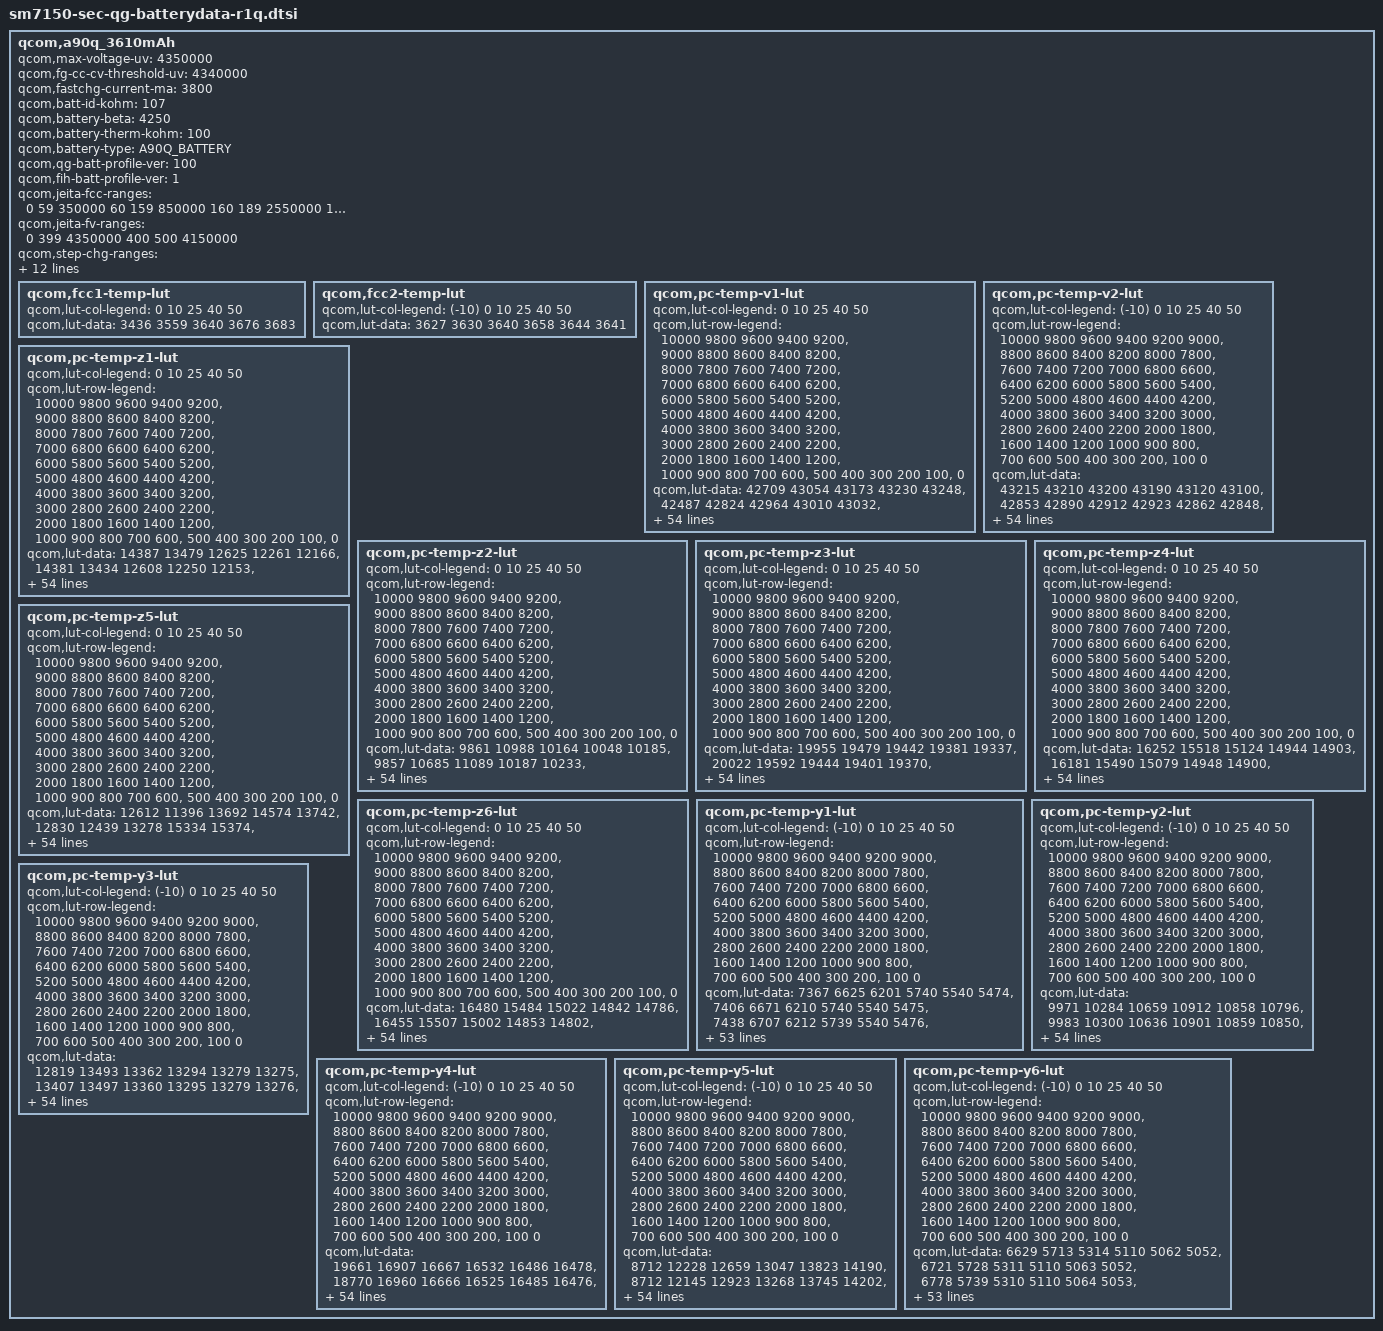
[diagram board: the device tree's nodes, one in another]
/*
 * Copyright (c) 2018, The Linux Foundation. All rights reserved.
 *
 * This program is free software; you can redistribute it and/or modify
 * it under the terms of the GNU General Public License version 2 and
 * only version 2 as published by the Free Software Foundation.
 *
 * This program is distributed in the hope that it will be useful,
 * but WITHOUT ANY WARRANTY; without even the implied warranty of
 * MERCHANTABILITY or FITNESS FOR A PARTICULAR PURPOSE.  See the
 * GNU General Public License for more details.
 */

qcom,a90q_3610mAh { /* A9S Battery is used for this (3720mAh) */
	/* A70Q BATTERY */
	qcom,max-voltage-uv = <4350000>;
	qcom,fg-cc-cv-threshold-uv = <4340000>;
	qcom,fastchg-current-ma = <3800>;
	qcom,batt-id-kohm = <107>;
	qcom,battery-beta = <4250>;
	qcom,battery-therm-kohm = <100>;
	qcom,battery-type = "A90Q_BATTERY";
	qcom,qg-batt-profile-ver = <100>;
	qcom,fih-batt-profile-ver = <1>;

	qcom,jeita-fcc-ranges = <0  59   350000
				60  159  850000
				160 189  2550000
				190 399  3800000
				400 490  1250000>;

	qcom,jeita-fv-ranges = <0   399  4350000
				400 500  4150000>;

	qcom,step-chg-ranges = <3400000  4299999  3800000
				4300000  4319999  3200000
				4320000  4350000  2550000>;
	qcom,vbat-avg-based-step-chg;
	qcom,taper-fcc;

	/* COOL = 18 DegC, WARM = 41 DegC */
	qcom,jeita-soft-thresholds = <0x4205 0x24EC>;
	/* COLD = 0 DegC, HOT = 50 DegC */
	qcom,jeita-hard-thresholds = <0x57F0 0x1C52>;

	qcom,qg-batt-aging-enable;
	qcom,vfloat-ranges = <0 299 4350000
				300 399 4330000
				400 699 4310000
				700 999 4290000
				1000 9999 4240000>;

	qcom,vbat-rechg-ranges = <0 299 4280000
				300 399 4260000
				400 699 4240000
				700 999 4220000
				1000 9999 4170000>;

	qcom,full-condition-soc-ranges = <0 299 93
				300 399 92
				400 699 91
				700 999 90
				1000 9999 89>;

	qcom,fcc1-temp-lut {
		qcom,lut-col-legend = <0 10 25 40 50>;
		qcom,lut-data = <3436 3559 3640 3676 3683>;
	};

	qcom,fcc2-temp-lut {
		qcom,lut-col-legend = <(-10) 0 10 25 40 50>;
		qcom,lut-data = <3627 3630 3640 3658 3644 3641>;
	};

	qcom,pc-temp-v1-lut {
		qcom,lut-col-legend = <0 10 25 40 50>;
		qcom,lut-row-legend = <10000 9800 9600 9400 9200>,
			<9000 8800 8600 8400 8200>,
			<8000 7800 7600 7400 7200>,
			<7000 6800 6600 6400 6200>,
			<6000 5800 5600 5400 5200>,
			<5000 4800 4600 4400 4200>,
			<4000 3800 3600 3400 3200>,
			<3000 2800 2600 2400 2200>,
			<2000 1800 1600 1400 1200>,
			<1000 900 800 700 600>,
			<500 400 300 200 100>,
			<0>;
		qcom,lut-data = <42709 43054 43173 43230 43248>,
			<42487 42824 42964 43010 43032>,
			<42271 42587 42744 42789 42815>,
			<42062 42354 42516 42568 42596>,
			<41857 42136 42288 42347 42376>,
			<41654 41924 42064 42127 42157>,
			<41457 41716 41843 41908 41937>,
			<41273 41506 41628 41692 41719>,
			<41114 41307 41417 41477 41508>,
			<40951 41130 41212 41266 41301>,
			<40745 40970 41022 41064 41097>,
			<40484 40788 40839 40874 40897>,
			<40242 40553 40648 40684 40701>,
			<40063 40309 40440 40488 40510>,
			<39912 40120 40238 40292 40322>,
			<39776 39969 40068 40115 40145>,
			<39653 39830 39917 39959 39985>,
			<39538 39701 39770 39807 39830>,
			<39423 39579 39630 39652 39671>,
			<39311 39443 39480 39495 39513>,
			<39200 39290 39272 39308 39336>,
			<39091 39125 38995 39060 39108>,
			<38981 38941 38787 38842 38889>,
			<38875 38738 38680 38721 38754>,
			<38769 38593 38601 38636 38657>,
			<38668 38512 38526 38552 38567>,
			<38578 38452 38459 38466 38475>,
			<38496 38402 38395 38386 38387>,
			<38425 38360 38335 38310 38305>,
			<38368 38322 38277 38239 38226>,
			<38322 38283 38223 38176 38157>,
			<38282 38247 38172 38120 38100>,
			<38249 38213 38125 38069 38048>,
			<38219 38182 38082 38017 37993>,
			<38188 38151 38044 37969 37938>,
			<38156 38115 38004 37920 37882>,
			<38119 38077 37967 37876 37827>,
			<38071 38029 37925 37828 37769>,
			<38003 37954 37856 37758 37695>,
			<37921 37856 37758 37664 37603>,
			<37818 37750 37650 37558 37499>,
			<37691 37630 37532 37440 37385>,
			<37551 37495 37401 37310 37259>,
			<37406 37340 37250 37162 37110>,
			<37290 37221 37131 37049 36993>,
			<37221 37153 37065 36979 36923>,
			<37203 37130 37044 36959 36904>,
			<37181 37110 37027 36946 36887>,
			<37151 37088 37008 36920 36862>,
			<37054 37010 36927 36824 36758>,
			<36767 36713 36622 36502 36430>,
			<36315 36268 36183 36060 35980>,
			<35747 35698 35619 35489 35400>,
			<34984 34932 34839 34717 34628>,
			<33764 33687 33622 33503 33403>,
			<30000 30000 30000 30000 30000>;
	};

	qcom,pc-temp-v2-lut {
		qcom,lut-col-legend = <(-10) 0 10 25 40 50>;
		qcom,lut-row-legend = <10000 9800 9600 9400 9200 9000>,
			<8800 8600 8400 8200 8000 7800>,
			<7600 7400 7200 7000 6800 6600>,
			<6400 6200 6000 5800 5600 5400>,
			<5200 5000 4800 4600 4400 4200>,
			<4000 3800 3600 3400 3200 3000>,
			<2800 2600 2400 2200 2000 1800>,
			<1600 1400 1200 1000 900 800>,
			<700 600 500 400 300 200>,
			<100 0>;
		qcom,lut-data = <43215 43210 43200 43190 43120 43100>,
			<42853 42890 42912 42923 42862 42848>,
			<42537 42595 42643 42668 42615 42606>,
			<42277 42330 42393 42428 42380 42373>,
			<42071 42092 42163 42203 42157 42150>,
			<41866 41866 41943 41983 41939 41932>,
			<41601 41637 41723 41764 41721 41715>,
			<41322 41415 41509 41549 41506 41500>,
			<41147 41213 41303 41337 41296 41290>,
			<41064 41042 41104 41126 41089 41082>,
			<40972 40869 40909 40922 40888 40880>,
			<40706 40661 40715 40730 40695 40687>,
			<40219 40423 40521 40545 40507 40499>,
			<39849 40188 40324 40357 40322 40317>,
			<39635 39956 40117 40156 40133 40138>,
			<39459 39734 39912 39965 39951 39965>,
			<39293 39545 39713 39806 39793 39804>,
			<39143 39378 39518 39666 39653 39656>,
			<38986 39211 39327 39501 39490 39487>,
			<38796 39028 39132 39275 39270 39269>,
			<38604 38849 38948 39043 39039 39044>,
			<38463 38696 38794 38863 38860 38866>,
			<38351 38563 38662 38711 38712 38718>,
			<38262 38440 38541 38581 38585 38590>,
			<38192 38320 38430 38472 38475 38479>,
			<38134 38207 38329 38376 38378 38382>,
			<38080 38116 38238 38286 38290 38292>,
			<38029 38041 38156 38202 38209 38209>,
			<37981 37980 38080 38125 38133 38132>,
			<37937 37935 38003 38054 38063 38060>,
			<37895 37897 37931 37988 37997 37994>,
			<37852 37861 37873 37927 37936 37932>,
			<37808 37828 37828 37871 37885 37880>,
			<37762 37793 37789 37814 37827 37820>,
			<37714 37753 37753 37756 37750 37730>,
			<37664 37708 37718 37697 37655 37613>,
			<37608 37658 37677 37634 37567 37509>,
			<37545 37604 37625 37568 37487 37424>,
			<37474 37541 37563 37498 37409 37345>,
			<37397 37465 37489 37425 37333 37267>,
			<37310 37372 37401 37347 37258 37191>,
			<37222 37268 37300 37253 37170 37102>,
			<37138 37148 37180 37132 37047 36978>,
			<37054 37024 37057 37013 36932 36865>,
			<36970 36912 36946 36912 36850 36791>,
			<36881 36827 36885 36875 36816 36759>,
			<36833 36795 36862 36862 36802 36746>,
			<36776 36755 36835 36840 36782 36725>,
			<36700 36694 36791 36797 36739 36678>,
			<36564 36584 36684 36669 36586 36506>,
			<36317 36349 36395 36315 36236 36134>,
			<35913 35914 35904 35817 35744 35641>,
			<35333 35323 35276 35176 35107 35004>,
			<34486 34514 34428 34288 34231 34137>,
			<33135 33244 33241 32987 33047 32871>,
			<28302 29120 28300 28436 28562 28479>;
	};

	qcom,pc-temp-z1-lut {
		qcom,lut-col-legend = <0 10 25 40 50>;
		qcom,lut-row-legend = <10000 9800 9600 9400 9200>,
			<9000 8800 8600 8400 8200>,
			<8000 7800 7600 7400 7200>,
			<7000 6800 6600 6400 6200>,
			<6000 5800 5600 5400 5200>,
			<5000 4800 4600 4400 4200>,
			<4000 3800 3600 3400 3200>,
			<3000 2800 2600 2400 2200>,
			<2000 1800 1600 1400 1200>,
			<1000 900 800 700 600>,
			<500 400 300 200 100>,
			<0>;
		qcom,lut-data = <14387 13479 12625 12261 12166>,
			<14381 13434 12608 12250 12153>,
			<14383 13418 12596 12242 12145>,
			<14392 13411 12587 12238 12144>,
			<14399 13408 12580 12235 12143>,
			<14394 13404 12573 12233 12144>,
			<14382 13400 12567 12231 12145>,
			<14377 13394 12563 12231 12146>,
			<14395 13388 12559 12232 12148>,
			<14413 13382 12556 12234 12153>,
			<14401 13371 12554 12236 12156>,
			<14364 13359 12551 12238 12157>,
			<14341 13343 12549 12239 12159>,
			<14339 13329 12548 12239 12159>,
			<14337 13327 12548 12239 12160>,
			<14335 13331 12548 12239 12160>,
			<14332 13335 12551 12241 12162>,
			<14328 13336 12555 12243 12164>,
			<14325 13338 12559 12245 12166>,
			<14320 13339 12562 12248 12168>,
			<14318 13344 12565 12250 12170>,
			<14320 13350 12568 12253 12172>,
			<14318 13352 12571 12255 12174>,
			<14315 13353 12576 12258 12177>,
			<14305 13355 12582 12262 12180>,
			<14292 13363 12587 12265 12184>,
			<14288 13372 12593 12269 12187>,
			<14290 13376 12599 12273 12192>,
			<14291 13376 12605 12277 12196>,
			<14289 13377 12611 12282 12199>,
			<14287 13380 12614 12287 12203>,
			<14286 13384 12616 12291 12208>,
			<14286 13390 12618 12295 12212>,
			<14288 13398 12623 12299 12215>,
			<14291 13407 12630 12302 12217>,
			<14297 13419 12636 12306 12219>,
			<14304 13434 12643 12308 12222>,
			<14305 13445 12649 12311 12224>,
			<14299 13453 12656 12314 12227>,
			<14294 13463 12663 12319 12230>,
			<14301 13464 12668 12324 12234>,
			<14312 13459 12672 12329 12237>,
			<14304 13459 12676 12334 12240>,
			<14283 13460 12682 12337 12244>,
			<14283 13451 12702 12343 12249>,
			<14273 13448 12700 12349 12251>,
			<14282 13449 12699 12348 12252>,
			<14263 13455 12699 12350 12255>,
			<14257 13458 12699 12351 12257>,
			<14276 13461 12706 12358 12260>,
			<14288 13478 12715 12365 12267>,
			<14289 13495 12730 12376 12277>,
			<14306 13528 12749 12391 12291>,
			<14328 13547 12783 12412 12310>,
			<14328 13547 12783 12412 12310>,
			<14328 13547 12783 12412 12310>;
	};

	qcom,pc-temp-z2-lut {
		qcom,lut-col-legend = <0 10 25 40 50>;
		qcom,lut-row-legend = <10000 9800 9600 9400 9200>,
			<9000 8800 8600 8400 8200>,
			<8000 7800 7600 7400 7200>,
			<7000 6800 6600 6400 6200>,
			<6000 5800 5600 5400 5200>,
			<5000 4800 4600 4400 4200>,
			<4000 3800 3600 3400 3200>,
			<3000 2800 2600 2400 2200>,
			<2000 1800 1600 1400 1200>,
			<1000 900 800 700 600>,
			<500 400 300 200 100>,
			<0>;
		qcom,lut-data = <9861 10988 10164 10048 10185>,
			<9857 10685 11089 10187 10233>,
			<9861 10236 11226 10328 10254>,
			<9871 9954 11043 10590 10274>,
			<9881 9926 10827 10838 10271>,
			<9895 9914 10620 10859 10254>,
			<9912 9905 10443 11005 10265>,
			<9921 9898 10396 11169 10274>,
			<9925 9895 10380 11184 10219>,
			<9927 9928 10373 11188 10112>,
			<9917 10017 10458 11181 10074>,
			<9874 10057 10610 11155 10090>,
			<9843 9995 10636 11135 10111>,
			<9845 9913 10417 11158 10121>,
			<9854 9901 10189 11200 10127>,
			<9862 9919 10167 11141 10136>,
			<9869 9942 10172 10605 10154>,
			<9874 9968 10178 10158 10175>,
			<9874 9997 10193 10181 10194>,
			<9865 10016 10214 10265 10215>,
			<9855 10027 10231 10290 10224>,
			<9852 10035 10249 10262 10214>,
			<9850 10042 10258 10230 10202>,
			<9851 10049 10243 10210 10210>,
			<9856 10053 10218 10185 10246>,
			<9865 10055 10215 10190 10270>,
			<9874 10056 10234 10240 10254>,
			<9882 10056 10255 10294 10232>,
			<9889 10053 10271 10323 10246>,
			<9896 10050 10285 10351 10291>,
			<9902 10051 10287 10354 10313>,
			<9908 10055 10285 10322 10236>,
			<9914 10059 10283 10291 10131>,
			<9919 10067 10284 10291 10122>,
			<9925 10076 10290 10302 10159>,
			<9932 10082 10294 10318 10202>,
			<9941 10088 10299 10351 10251>,
			<9949 10095 10306 10391 10297>,
			<9958 10104 10318 10422 10311>,
			<9969 10114 10336 10453 10317>,
			<9985 10123 10348 10467 10319>,
			<10007 10129 10354 10462 10318>,
			<10039 10141 10360 10450 10317>,
			<10106 10168 10366 10364 10322>,
			<10446 10344 10431 10369 10343>,
			<10387 10415 10446 10363 10305>,
			<10336 10422 10434 10358 10328>,
			<10313 10453 10439 10385 10320>,
			<10262 10588 10468 10398 10375>,
			<10248 10614 10488 10481 10406>,
			<10242 10508 10554 10408 10218>,
			<10142 10498 10509 10325 10133>,
			<10015 10448 10529 10273 10077>,
			<9842 10332 10473 10229 10048>,
			<9842 10332 10473 10229 10048>,
			<9842 10332 10473 10229 10048>;
	};

	qcom,pc-temp-z3-lut {
		qcom,lut-col-legend = <0 10 25 40 50>;
		qcom,lut-row-legend = <10000 9800 9600 9400 9200>,
			<9000 8800 8600 8400 8200>,
			<8000 7800 7600 7400 7200>,
			<7000 6800 6600 6400 6200>,
			<6000 5800 5600 5400 5200>,
			<5000 4800 4600 4400 4200>,
			<4000 3800 3600 3400 3200>,
			<3000 2800 2600 2400 2200>,
			<2000 1800 1600 1400 1200>,
			<1000 900 800 700 600>,
			<500 400 300 200 100>,
			<0>;
		qcom,lut-data = <19955 19479 19442 19381 19337>,
			<20022 19592 19444 19401 19370>,
			<20035 19705 19458 19417 19392>,
			<20033 19762 19499 19431 19400>,
			<20024 19769 19529 19443 19404>,
			<20004 19771 19538 19453 19405>,
			<19974 19772 19544 19473 19409>,
			<19945 19769 19547 19487 19414>,
			<19912 19767 19546 19488 19409>,
			<19887 19770 19546 19488 19395>,
			<19903 19780 19552 19485 19386>,
			<19983 19784 19560 19471 19382>,
			<20042 19776 19556 19460 19380>,
			<20028 19761 19527 19456 19378>,
			<19986 19742 19495 19454 19377>,
			<19951 19716 19479 19446 19375>,
			<19927 19693 19467 19413 19366>,
			<19910 19676 19463 19386 19358>,
			<19910 19662 19464 19386 19358>,
			<19933 19660 19467 19388 19361>,
			<19966 19680 19475 19389 19363>,
			<19993 19702 19491 19391 19361>,
			<20022 19713 19501 19393 19356>,
			<20040 19722 19494 19386 19350>,
			<20046 19724 19482 19371 19341>,
			<20050 19722 19475 19366 19337>,
			<20051 19717 19469 19371 19348>,
			<20043 19711 19467 19379 19365>,
			<20031 19703 19470 19392 19380>,
			<20018 19694 19478 19410 19397>,
			<20002 19688 19484 19416 19404>,
			<19985 19682 19491 19415 19396>,
			<19965 19676 19495 19412 19384>,
			<19944 19670 19493 19409 19376>,
			<19924 19664 19490 19403 19371>,
			<19903 19659 19485 19398 19368>,
			<19884 19654 19479 19393 19365>,
			<19867 19650 19472 19388 19364>,
			<19852 19646 19467 19386 19363>,
			<19837 19642 19463 19383 19363>,
			<19819 19636 19461 19382 19363>,
			<19798 19626 19459 19384 19362>,
			<19774 19615 19457 19387 19361>,
			<19736 19602 19451 19378 19362>,
			<19575 19537 19431 19364 19357>,
			<19488 19494 19416 19359 19348>,
			<19381 19485 19410 19358 19337>,
			<19354 19472 19408 19347 19337>,
			<19340 19426 19393 19344 19327>,
			<19340 19419 19386 19335 19330>,
			<19357 19462 19380 19347 19356>,
			<19364 19451 19381 19349 19360>,
			<19371 19442 19359 19353 19358>,
			<19372 19358 19356 19348 19360>,
			<19372 19358 19356 19348 19360>,
			<19372 19358 19356 19348 19360>;
	};

	qcom,pc-temp-z4-lut {
		qcom,lut-col-legend = <0 10 25 40 50>;
		qcom,lut-row-legend = <10000 9800 9600 9400 9200>,
			<9000 8800 8600 8400 8200>,
			<8000 7800 7600 7400 7200>,
			<7000 6800 6600 6400 6200>,
			<6000 5800 5600 5400 5200>,
			<5000 4800 4600 4400 4200>,
			<4000 3800 3600 3400 3200>,
			<3000 2800 2600 2400 2200>,
			<2000 1800 1600 1400 1200>,
			<1000 900 800 700 600>,
			<500 400 300 200 100>,
			<0>;
		qcom,lut-data = <16252 15518 15124 14944 14903>,
			<16181 15490 15079 14948 14900>,
			<16076 15380 15025 14938 14894>,
			<15936 15267 14962 14905 14877>,
			<15819 15183 14910 14856 14849>,
			<15742 15112 14876 14815 14825>,
			<15679 15057 14848 14769 14801>,
			<15620 15018 14821 14729 14780>,
			<15566 14979 14797 14704 14769>,
			<15512 14920 14773 14686 14761>,
			<15450 14848 14733 14675 14753>,
			<15381 14819 14691 14667 14741>,
			<15324 14842 14683 14662 14731>,
			<15291 14873 14717 14656 14722>,
			<15267 14876 14753 14651 14714>,
			<15242 14857 14752 14652 14708>,
			<15215 14834 14739 14676 14703>,
			<15185 14813 14729 14699 14700>,
			<15145 14791 14722 14704 14700>,
			<15084 14779 14717 14707 14703>,
			<15021 14773 14741 14720 14711>,
			<14971 14769 14830 14799 14778>,
			<14924 14791 14881 14868 14854>,
			<14896 14859 14880 14871 14862>,
			<14887 14894 14876 14868 14858>,
			<14881 14889 14870 14863 14852>,
			<14880 14878 14856 14845 14828>,
			<14880 14866 14839 14818 14794>,
			<14880 14852 14818 14789 14762>,
			<14877 14836 14794 14754 14729>,
			<14868 14823 14772 14731 14710>,
			<14857 14811 14752 14716 14704>,
			<14849 14799 14737 14708 14700>,
			<14840 14787 14731 14708 14700>,
			<14832 14777 14726 14710 14703>,
			<14826 14769 14724 14712 14707>,
			<14820 14761 14723 14713 14709>,
			<14814 14758 14723 14715 14712>,
			<14808 14759 14727 14720 14716>,
			<14804 14761 14736 14729 14723>,
			<14805 14761 14740 14734 14726>,
			<14807 14757 14732 14724 14721>,
			<14801 14753 14725 14717 14716>,
			<14789 14745 14723 14725 14716>,
			<14781 14721 14702 14710 14705>,
			<14872 14731 14684 14687 14683>,
			<14984 14734 14678 14674 14678>,
			<15011 14740 14667 14664 14657>,
			<15017 14784 14675 14654 14647>,
			<15010 14788 14687 14674 14654>,
			<15002 14756 14719 14695 14664>,
			<15016 14777 14723 14699 14665>,
			<15024 14796 14749 14696 14670>,
			<15042 14896 14762 14704 14669>,
			<15042 14896 14762 14704 14669>,
			<15042 14896 14762 14704 14669>;
	};

	qcom,pc-temp-z5-lut {
		qcom,lut-col-legend = <0 10 25 40 50>;
		qcom,lut-row-legend = <10000 9800 9600 9400 9200>,
			<9000 8800 8600 8400 8200>,
			<8000 7800 7600 7400 7200>,
			<7000 6800 6600 6400 6200>,
			<6000 5800 5600 5400 5200>,
			<5000 4800 4600 4400 4200>,
			<4000 3800 3600 3400 3200>,
			<3000 2800 2600 2400 2200>,
			<2000 1800 1600 1400 1200>,
			<1000 900 800 700 600>,
			<500 400 300 200 100>,
			<0>;
		qcom,lut-data = <12612 11396 13692 14574 13742>,
			<12830 12439 13278 15334 15374>,
			<12961 13754 13428 16023 16461>,
			<13058 14738 14443 16574 16860>,
			<13095 15151 15665 17139 17062>,
			<13080 15436 16674 18059 17216>,
			<13040 15754 17654 20284 17887>,
			<12986 16075 18585 23033 18587>,
			<12886 16468 19509 26018 18278>,
			<12799 17249 20647 28895 17391>,
			<13021 18531 23747 29906 17091>,
			<13953 19342 28129 30151 17450>,
			<14623 19587 29133 30462 17998>,
			<14504 19630 24528 31632 18677>,
			<14147 19326 19751 33385 19539>,
			<13957 18576 19355 33061 19853>,
			<13959 18093 19619 26653 19685>,
			<13989 18376 20068 21225 19486>,
			<14147 19334 21816 21891 20171>,
			<14982 21293 24863 24000 22449>,
			<16259 28659 29559 25229 23537>,
			<17986 36858 37103 25714 22540>,
			<20833 40976 40829 25663 20839>,
			<23935 43964 36142 23374 18985>,
			<27400 44991 28441 18911 16343>,
			<30867 42402 24499 17025 15204>,
			<32870 37915 22075 16746 15524>,
			<34169 34643 21019 16767 16212>,
			<34928 31900 21296 17702 17924>,
			<34759 30002 22109 20198 22076>,
			<33728 29027 23422 22658 24292>,
			<32429 28309 26639 25004 24312>,
			<30905 27941 29869 27110 24306>,
			<29074 27786 32012 28659 24625>,
			<27576 27735 33786 29976 25834>,
			<26239 27893 34176 30414 26555>,
			<25129 28342 32805 29459 26384>,
			<24630 28565 30856 27784 25962>,
			<24628 28755 29122 25866 25124>,
			<24723 29057 27352 23296 23062>,
			<24356 28791 26482 22194 21414>,
			<23716 26850 26212 22677 20824>,
			<23955 26171 25913 23014 20474>,
			<24096 26435 24552 20292 20092>,
			<20016 25197 24934 19795 19929>,
			<16439 20063 23741 20132 19448>,
			<12763 18793 22567 20558 17818>,
			<11913 17839 22990 19351 19941>,
			<11769 15537 20310 20354 20305>,
			<11848 15735 18599 16727 18692>,
			<12045 16845 16007 15571 18755>,
			<11985 15424 15626 15040 18414>,
			<11908 14587 13828 15042 16934>,
			<11724 12129 13273 14188 16576>,
			<11724 12129 13273 14188 16576>,
			<11724 12129 13273 14188 16576>;
	};

	qcom,pc-temp-z6-lut {
		qcom,lut-col-legend = <0 10 25 40 50>;
		qcom,lut-row-legend = <10000 9800 9600 9400 9200>,
			<9000 8800 8600 8400 8200>,
			<8000 7800 7600 7400 7200>,
			<7000 6800 6600 6400 6200>,
			<6000 5800 5600 5400 5200>,
			<5000 4800 4600 4400 4200>,
			<4000 3800 3600 3400 3200>,
			<3000 2800 2600 2400 2200>,
			<2000 1800 1600 1400 1200>,
			<1000 900 800 700 600>,
			<500 400 300 200 100>,
			<0>;
		qcom,lut-data = <16480 15484 15022 14842 14786>,
			<16455 15507 15002 14853 14802>,
			<16406 15496 14988 14857 14810>,
			<16326 15480 14978 14850 14806>,
			<16251 15449 14969 14836 14797>,
			<16194 15405 14958 14825 14789>,
			<16143 15372 14946 14816 14782>,
			<16093 15349 14934 14807 14774>,
			<16038 15327 14923 14798 14766>,
			<15994 15300 14911 14791 14757>,
			<15980 15270 14898 14782 14749>,
			<15975 15256 14884 14772 14742>,
			<15969 15253 14876 14763 14736>,
			<15949 15251 14873 14759 14731>,
			<15911 15244 14870 14756 14727>,
			<15878 15221 14863 14751 14723>,
			<15853 15196 14851 14742 14715>,
			<15832 15177 14845 14737 14710>,
			<15814 15161 14844 14737 14710>,
			<15799 15158 14843 14740 14712>,
			<15787 15164 14856 14747 14718>,
			<15779 15175 14904 14783 14746>,
			<15773 15195 14932 14814 14776>,
			<15769 15230 14929 14813 14778>,
			<15768 15246 14923 14805 14773>,
			<15767 15243 14916 14799 14767>,
			<15764 15238 14909 14794 14763>,
			<15758 15232 14901 14789 14758>,
			<15750 15223 14895 14784 14754>,
			<15740 15213 14889 14779 14750>,
			<15727 15205 14885 14774 14746>,
			<15714 15199 14880 14768 14738>,
			<15699 15192 14876 14762 14731>,
			<15684 15186 14874 14760 14728>,
			<15672 15180 14871 14758 14726>,
			<15660 15176 14868 14756 14725>,
			<15650 15173 14864 14755 14725>,
			<15643 15172 14862 14753 14726>,
			<15637 15173 14863 14754 14726>,
			<15630 15175 14866 14757 14729>,
			<15623 15175 14868 14759 14731>,
			<15615 15171 14865 14757 14729>,
			<15604 15167 14862 14755 14727>,
			<15585 15162 14860 14754 14728>,
			<15508 15124 14843 14742 14721>,
			<15501 15111 14828 14730 14708>,
			<15493 15107 14822 14724 14700>,
			<15491 15104 14817 14714 14691>,
			<15490 15102 14814 14709 14681>,
			<15492 15102 14817 14713 14686>,
			<15506 15117 14831 14731 14707>,
			<15526 15129 14836 14736 14712>,
			<15547 15142 14840 14740 14716>,
			<15578 15160 14851 14746 14721>,
			<15578 15160 14851 14746 14721>,
			<15578 15160 14851 14746 14721>;
	};

	qcom,pc-temp-y1-lut {
		qcom,lut-col-legend = <(-10) 0 10 25 40 50>;
		qcom,lut-row-legend = <10000 9800 9600 9400 9200 9000>,
			<8800 8600 8400 8200 8000 7800>,
			<7600 7400 7200 7000 6800 6600>,
			<6400 6200 6000 5800 5600 5400>,
			<5200 5000 4800 4600 4400 4200>,
			<4000 3800 3600 3400 3200 3000>,
			<2800 2600 2400 2200 2000 1800>,
			<1600 1400 1200 1000 900 800>,
			<700 600 500 400 300 200>,
			<100 0>;
		qcom,lut-data = <7367 6625 6201 5740 5540 5474>,
			<7406 6671 6210 5740 5540 5475>,
			<7438 6707 6212 5739 5540 5476>,
			<7462 6732 6210 5738 5539 5477>,
			<7477 6747 6206 5736 5539 5478>,
			<7483 6753 6204 5735 5538 5478>,
			<7476 6752 6202 5733 5538 5478>,
			<7462 6750 6197 5732 5537 5478>,
			<7454 6747 6195 5732 5536 5478>,
			<7449 6733 6193 5731 5536 5478>,
			<7446 6719 6192 5730 5535 5478>,
			<7447 6718 6192 5730 5536 5479>,
			<7451 6723 6191 5730 5537 5480>,
			<7457 6727 6191 5729 5537 5480>,
			<7471 6729 6191 5730 5538 5480>,
			<7485 6730 6192 5731 5538 5480>,
			<7483 6731 6195 5732 5539 5481>,
			<7469 6733 6200 5733 5542 5482>,
			<7463 6734 6202 5734 5543 5483>,
			<7474 6733 6204 5737 5543 5484>,
			<7486 6732 6205 5740 5542 5484>,
			<7481 6735 6204 5743 5543 5485>,
			<7456 6747 6203 5745 5544 5487>,
			<7438 6755 6203 5748 5546 5489>,
			<7445 6756 6204 5751 5549 5493>,
			<7460 6756 6205 5754 5552 5496>,
			<7469 6754 6207 5757 5554 5497>,
			<7471 6741 6210 5762 5555 5497>,
			<7470 6729 6215 5765 5557 5498>,
			<7460 6730 6218 5769 5561 5499>,
			<7445 6733 6222 5773 5566 5503>,
			<7439 6734 6225 5778 5570 5506>,
			<7436 6742 6228 5784 5573 5511>,
			<7435 6751 6230 5789 5575 5515>,
			<7433 6754 6232 5793 5579 5516>,
			<7432 6751 6234 5795 5582 5516>,
			<7430 6746 6236 5797 5584 5518>,
			<7439 6750 6239 5799 5585 5520>,
			<7448 6756 6242 5801 5587 5522>,
			<7443 6753 6244 5806 5588 5524>,
			<7423 6737 6247 5814 5589 5525>,
			<7408 6728 6250 5818 5591 5527>,
			<7423 6728 6256 5818 5595 5532>,
			<7454 6731 6257 5820 5599 5535>,
			<7427 6745 6260 5821 5601 5536>,
			<7408 6746 6262 5831 5604 5536>,
			<7417 6743 6258 5835 5606 5537>,
			<7408 6753 6259 5833 5606 5538>,
			<7428 6767 6272 5832 5604 5539>,
			<7450 6753 6275 5837 5603 5539>,
			<7440 6755 6273 5846 5612 5543>,
			<7449 6767 6285 5858 5622 5550>,
			<7474 6799 6305 5881 5633 5559>,
			<7568 6854 6338 5906 5648 5571>,
			<7568 6854 6338 5906 5648 5571>,
			<7568 6854 6338 5906 5648 5571>;
	};

	qcom,pc-temp-y2-lut {
		qcom,lut-col-legend = <(-10) 0 10 25 40 50>;
		qcom,lut-row-legend = <10000 9800 9600 9400 9200 9000>,
			<8800 8600 8400 8200 8000 7800>,
			<7600 7400 7200 7000 6800 6600>,
			<6400 6200 6000 5800 5600 5400>,
			<5200 5000 4800 4600 4400 4200>,
			<4000 3800 3600 3400 3200 3000>,
			<2800 2600 2400 2200 2000 1800>,
			<1600 1400 1200 1000 900 800>,
			<700 600 500 400 300 200>,
			<100 0>;
		qcom,lut-data = <9971 10284 10659 10912 10858 10796>,
			<9983 10300 10636 10901 10859 10850>,
			<10010 10311 10613 10888 10858 10879>,
			<10044 10318 10591 10874 10855 10890>,
			<10078 10321 10572 10861 10851 10888>,
			<10106 10321 10558 10849 10846 10881>,
			<10168 10313 10549 10815 10841 10856>,
			<10268 10302 10542 10764 10835 10814>,
			<10299 10304 10534 10754 10826 10796>,
			<10273 10368 10524 10775 10808 10790>,
			<10249 10438 10517 10792 10792 10786>,
			<10213 10463 10530 10787 10790 10780>,
			<10098 10485 10569 10777 10795 10771>,
			<10029 10492 10606 10779 10795 10766>,
			<9876 10500 10642 10791 10776 10764>,
			<9709 10515 10671 10808 10760 10768>,
			<9682 10536 10680 10836 10789 10802>,
			<9674 10573 10685 10881 10876 10878>,
			<9669 10607 10693 10905 10927 10918>,
			<9666 10638 10722 10912 10911 10918>,
			<9664 10666 10762 10917 10886 10913>,
			<9662 10681 10790 10937 10902 10921>,
			<9661 10695 10817 10974 10952 10941>,
			<9660 10703 10840 10999 10987 10963>,
			<9659 10714 10866 11020 11008 10984>,
			<9658 10734 10891 11042 11028 11009>,
			<9658 10748 10896 11057 11041 11038>,
			<9657 10770 10897 11069 11066 11075>,
			<9656 10777 10902 11076 11087 11095>,
			<9656 10669 10919 11076 11095 11071>,
			<9655 10387 10940 11076 11099 11034>,
			<9655 10238 10944 11079 11106 11045>,
			<9654 10218 10925 11091 11143 11222>,
			<9654 10199 10897 11098 11177 11388>,
			<9654 10104 10874 11081 11169 11349>,
			<9654 9913 10851 11056 11141 11193>,
			<9653 9792 10826 11053 11127 11105>,
			<9653 9724 10799 11064 11126 11091>,
			<9653 9683 10769 11073 11127 11085>,
			<9653 9673 10734 11070 11117 11081>,
			<9653 9668 10694 11059 11097 11072>,
			<9653 9664 10652 11048 11087 11064>,
			<9653 9660 10612 11038 11077 11065>,
			<9653 9658 10566 11009 11053 11058>,
			<9652 9656 10502 10941 11004 10971>,
			<9652 9654 10432 10937 10996 10886>,
			<9652 9654 10402 10925 10981 10827>,
			<9652 9653 10380 10948 10962 10796>,
			<9652 9653 10358 10930 10934 10779>,
			<9652 9653 10321 10920 10946 10792>,
			<9652 9652 10117 10862 10917 10773>,
			<9652 9652 9902 10804 10833 10699>,
			<9651 9651 9704 10743 10766 10627>,
			<9650 9651 9666 10629 10692 10518>,
			<9650 9651 9666 10629 10692 10518>,
			<9650 9651 9666 10629 10692 10518>;
	};

	qcom,pc-temp-y3-lut {
		qcom,lut-col-legend = <(-10) 0 10 25 40 50>;
		qcom,lut-row-legend = <10000 9800 9600 9400 9200 9000>,
			<8800 8600 8400 8200 8000 7800>,
			<7600 7400 7200 7000 6800 6600>,
			<6400 6200 6000 5800 5600 5400>,
			<5200 5000 4800 4600 4400 4200>,
			<4000 3800 3600 3400 3200 3000>,
			<2800 2600 2400 2200 2000 1800>,
			<1600 1400 1200 1000 900 800>,
			<700 600 500 400 300 200>,
			<100 0>;
		qcom,lut-data = <12819 13493 13362 13294 13279 13275>,
			<13407 13497 13360 13295 13279 13276>,
			<13781 13502 13361 13296 13280 13276>,
			<13989 13508 13363 13297 13280 13277>,
			<14078 13515 13366 13298 13281 13278>,
			<14099 13522 13369 13299 13281 13279>,
			<13980 13533 13371 13299 13281 13279>,
			<13729 13544 13375 13298 13282 13280>,
			<13643 13545 13377 13298 13283 13280>,
			<13682 13524 13381 13299 13286 13280>,
			<13725 13501 13386 13299 13289 13280>,
			<13720 13500 13391 13303 13291 13282>,
			<13691 13505 13395 13311 13292 13286>,
			<13664 13506 13397 13315 13292 13288>,
			<13606 13497 13395 13316 13291 13287>,
			<13549 13485 13392 13317 13289 13286>,
			<13549 13475 13387 13318 13290 13287>,
			<13572 13465 13380 13320 13295 13290>,
			<13586 13454 13372 13321 13298 13292>,
			<13573 13439 13362 13316 13293 13289>,
			<13550 13424 13353 13309 13287 13283>,
			<13540 13412 13349 13304 13284 13280>,
			<13535 13404 13347 13300 13282 13279>,
			<13540 13396 13345 13298 13281 13278>,
			<13565 13386 13340 13299 13281 13277>,
			<13605 13376 13335 13300 13281 13277>,
			<13642 13368 13335 13300 13281 13278>,
			<13678 13355 13337 13299 13282 13279>,
			<13718 13347 13338 13298 13283 13280>,
			<13764 13351 13334 13299 13283 13279>,
			<13816 13363 13329 13300 13283 13278>,
			<13869 13370 13326 13301 13283 13278>,
			<13925 13372 13328 13302 13284 13280>,
			<13985 13372 13330 13302 13285 13281>,
			<14048 13370 13335 13301 13285 13279>,
			<14115 13372 13341 13300 13285 13277>,
			<14188 13382 13344 13299 13284 13276>,
			<14269 13407 13344 13298 13282 13276>,
			<14357 13436 13344 13298 13280 13277>,
			<14446 13460 13344 13298 13280 13277>,
			<14538 13490 13345 13298 13282 13277>,
			<14631 13529 13347 13297 13283 13277>,
			<14722 13606 13352 13298 13283 13278>,
			<14817 13717 13357 13299 13282 13278>,
			<14927 13862 13362 13300 13283 13278>,
			<15061 14072 13374 13303 13288 13284>,
			<15123 14174 13380 13307 13290 13287>,
			<15073 14178 13383 13309 13295 13290>,
			<15139 14251 13394 13315 13297 13292>,
			<15294 14428 13405 13318 13295 13288>,
			<15479 14623 13416 13312 13293 13285>,
			<15747 14870 13437 13315 13296 13289>,
			<16146 15236 13494 13326 13299 13294>,
			<17279 15608 13622 13338 13303 13297>,
			<17279 15608 13622 13338 13303 13297>,
			<17279 15608 13622 13338 13303 13297>;
	};

	qcom,pc-temp-y4-lut {
		qcom,lut-col-legend = <(-10) 0 10 25 40 50>;
		qcom,lut-row-legend = <10000 9800 9600 9400 9200 9000>,
			<8800 8600 8400 8200 8000 7800>,
			<7600 7400 7200 7000 6800 6600>,
			<6400 6200 6000 5800 5600 5400>,
			<5200 5000 4800 4600 4400 4200>,
			<4000 3800 3600 3400 3200 3000>,
			<2800 2600 2400 2200 2000 1800>,
			<1600 1400 1200 1000 900 800>,
			<700 600 500 400 300 200>,
			<100 0>;
		qcom,lut-data = <19661 16907 16667 16532 16486 16478>,
			<18770 16960 16666 16525 16485 16476>,
			<18205 17003 16668 16523 16486 16476>,
			<17892 17037 16671 16523 16487 16476>,
			<17757 17059 16674 16526 16489 16477>,
			<17726 17069 16678 16530 16492 16478>,
			<17906 17062 16685 16536 16495 16480>,
			<18307 17045 16696 16545 16499 16484>,
			<18507 17052 16704 16554 16502 16487>,
			<18594 17197 16710 16562 16504 16492>,
			<18617 17351 16719 16570 16506 16497>,
			<18378 17367 16758 16577 16511 16501>,
			<17856 17315 16835 16585 16519 16504>,
			<17623 17260 16878 16593 16528 16509>,
			<17651 17170 16896 16604 16539 16518>,
			<17688 17077 16905 16618 16552 16530>,
			<17646 17040 16887 16645 16572 16545>,
			<17531 17020 16820 16685 16600 16565>,
			<17404 16994 16755 16699 16611 16573>,
			<17264 16945 16698 16647 16583 16553>,
			<17131 16888 16650 16577 16540 16522>,
			<17073 16850 16626 16543 16514 16503>,
			<17042 16823 16611 16519 16494 16487>,
			<17025 16796 16605 16508 16486 16481>,
			<17015 16753 16607 16507 16487 16481>,
			<17010 16709 16610 16507 16488 16482>,
			<17009 16698 16610 16510 16491 16485>,
			<17012 16701 16608 16519 16498 16490>,
			<17016 16707 16604 16527 16506 16498>,
			<17017 16716 16599 16534 16516 16507>,
			<17018 16732 16592 16542 16527 16518>,
			<17019 16750 16590 16547 16539 16529>,
			<17027 16768 16593 16552 16554 16543>,
			<17035 16785 16599 16554 16563 16552>,
			<17041 16810 16606 16548 16548 16538>,
			<17048 16846 16615 16536 16512 16502>,
			<17051 16867 16623 16524 16492 16483>,
			<17049 16876 16631 16512 16485 16478>,
			<17047 16883 16639 16505 16481 16476>,
			<17047 16891 16648 16508 16484 16477>,
			<17049 16899 16658 16518 16491 16483>,
			<17054 16901 16667 16526 16494 16487>,
			<17065 16896 16676 16532 16494 16485>,
			<17087 16892 16686 16532 16493 16481>,
			<17135 16908 16697 16526 16487 16476>,
			<17214 16963 16737 16551 16500 16492>,
			<17253 17012 16765 16566 16517 16514>,
			<17218 17044 16780 16580 16539 16545>,
			<17220 17089 16832 16613 16571 16569>,
			<17238 17148 16880 16620 16540 16530>,
			<17218 17172 16882 16566 16497 16486>,
			<17183 17158 16885 16576 16497 16489>,
			<17186 17158 16959 16611 16511 16500>,
			<17466 17205 17058 16694 16564 16554>,
			<17466 17205 17058 16694 16564 16554>,
			<17466 17205 17058 16694 16564 16554>;
	};

	qcom,pc-temp-y5-lut {
		qcom,lut-col-legend = <(-10) 0 10 25 40 50>;
		qcom,lut-row-legend = <10000 9800 9600 9400 9200 9000>,
			<8800 8600 8400 8200 8000 7800>,
			<7600 7400 7200 7000 6800 6600>,
			<6400 6200 6000 5800 5600 5400>,
			<5200 5000 4800 4600 4400 4200>,
			<4000 3800 3600 3400 3200 3000>,
			<2800 2600 2400 2200 2000 1800>,
			<1600 1400 1200 1000 900 800>,
			<700 600 500 400 300 200>,
			<100 0>;
		qcom,lut-data = <8712 12228 12659 13047 13823 14190>,
			<8712 12145 12923 13268 13745 14202>,
			<9136 12225 13085 13356 13640 14188>,
			<11630 12403 13170 13344 13518 14152>,
			<13149 12613 13202 13259 13386 14099>,
			<13728 12789 13207 13134 13251 14030>,
			<12872 12997 13180 12913 13079 13895>,
			<11072 13251 13141 12609 12900 13676>,
			<10587 13243 13136 12395 12906 13455>,
			<12047 12565 13072 12224 13416 13168>,
			<13644 11944 13019 12130 13870 12972>,
			<13866 12490 13059 12247 13790 13169>,
			<13352 14114 13132 12565 13490 13675>,
			<12993 15015 13290 12814 13200 13849>,
			<12175 15046 14039 12975 12864 13443>,
			<11341 14907 14974 13139 12619 13014>,
			<11552 14908 15556 13339 12691 13046>,
			<12376 15088 16032 13602 13059 13318>,
			<12873 15147 16189 14020 13504 13650>,
			<12523 14950 15711 15165 14198 14203>,
			<11879 14758 15096 16243 14834 14807>,
			<11541 14777 14975 16148 14964 15052>,
			<11059 15133 15097 15484 14998 15168>,
			<10777 15426 15139 15117 14992 15173>,
			<10793 15289 14719 15485 14817 14985>,
			<10822 14746 14179 15931 14568 14763>,
			<10829 14196 14247 15823 14606 14783>,
			<10817 12941 14988 15398 15043 15053>,
			<10805 12046 15494 15237 15333 15233>,
			<10851 12073 15199 15474 15217 14993>,
			<10965 12231 14510 15901 15015 14573>,
			<11029 12423 14160 16406 15049 14555>,
			<11051 12689 14221 17325 15773 15392>,
			<11064 12851 14479 17801 16634 16149>,
			<11086 12537 15045 17628 17232 15969>,
			<11121 11850 15840 17225 17725 15444>,
			<11130 11640 16079 16896 17787 15270>,
			<11138 11712 15696 16504 16854 15534>,
			<11147 11787 15145 16280 15696 15768>,
			<11118 11741 14722 16075 15294 15602>,
			<10989 11536 14333 15533 15318 15044>,
			<10906 11421 14186 15187 15496 14737>,
			<10936 11446 14369 14866 15373 14862>,
			<10997 11462 14491 14894 14996 14977>,
			<11060 11407 14206 15014 14906 14554>,
			<11158 11468 14194 14246 15037 14856>,
			<11243 11549 13934 14443 14678 14859>,
			<11345 11502 13767 14408 15147 14895>,
			<11540 11646 13870 14707 14982 14794>,
			<11616 11938 13851 14964 15040 14382>,
			<11534 12006 13258 14914 15966 14486>,
			<11239 11610 12568 14715 16823 15844>,
			<11069 11538 11865 15827 16913 17224>,
			<10470 11375 11776 16371 17420 17500>,
			<10470 11375 11776 16371 17420 17500>,
			<10470 11375 11776 16371 17420 17500>;
	};

	qcom,pc-temp-y6-lut {
		qcom,lut-col-legend = <(-10) 0 10 25 40 50>;
		qcom,lut-row-legend = <10000 9800 9600 9400 9200 9000>,
			<8800 8600 8400 8200 8000 7800>,
			<7600 7400 7200 7000 6800 6600>,
			<6400 6200 6000 5800 5600 5400>,
			<5200 5000 4800 4600 4400 4200>,
			<4000 3800 3600 3400 3200 3000>,
			<2800 2600 2400 2200 2000 1800>,
			<1600 1400 1200 1000 900 800>,
			<700 600 500 400 300 200>,
			<100 0>;
		qcom,lut-data = <6629 5713 5314 5110 5062 5052>,
			<6721 5728 5311 5110 5063 5052>,
			<6778 5739 5310 5110 5064 5053>,
			<6808 5747 5310 5111 5065 5054>,
			<6821 5751 5310 5112 5066 5055>,
			<6823 5754 5310 5114 5067 5056>,
			<6801 5752 5312 5115 5069 5057>,
			<6753 5748 5314 5118 5070 5058>,
			<6742 5749 5317 5120 5072 5060>,
			<6794 5768 5320 5122 5074 5061>,
			<6843 5788 5323 5125 5077 5063>,
			<6786 5789 5336 5130 5080 5065>,
			<6614 5778 5360 5137 5083 5069>,
			<6517 5763 5371 5143 5086 5072>,
			<6493 5734 5373 5146 5088 5074>,
			<6478 5701 5374 5151 5091 5076>,
			<6469 5685 5368 5159 5097 5082>,
			<6463 5676 5343 5172 5109 5090>,
			<6455 5664 5317 5176 5114 5094>,
			<6427 5642 5294 5158 5102 5085>,
			<6393 5618 5274 5134 5085 5072>,
			<6388 5607 5266 5120 5075 5064>,
			<6399 5602 5261 5110 5068 5058>,
			<6414 5598 5259 5106 5065 5056>,
			<6440 5592 5258 5107 5065 5056>,
			<6480 5586 5258 5108 5066 5056>,
			<6516 5585 5259 5109 5067 5057>,
			<6550 5594 5263 5111 5070 5059>,
			<6586 5609 5266 5114 5073 5062>,
			<6626 5628 5265 5117 5076 5065>,
			<6668 5656 5264 5121 5079 5067>,
			<6712 5684 5263 5124 5083 5071>,
			<6757 5713 5269 5127 5089 5076>,
			<6805 5744 5278 5129 5093 5080>,
			<6857 5778 5288 5127 5089 5075>,
			<6911 5814 5299 5123 5078 5063>,
			<6968 5853 5310 5120 5072 5057>,
			<7027 5897 5319 5117 5069 5057>,
			<7088 5945 5329 5115 5067 5056>,
			<7152 5999 5341 5117 5068 5057>,
			<7219 6060 5355 5120 5071 5059>,
			<7288 6131 5373 5123 5073 5060>,
			<7359 6219 5398 5126 5073 5060>,
			<7436 6327 5428 5128 5072 5059>,
			<7527 6462 5465 5129 5072 5059>,
			<7646 6653 5531 5141 5080 5068>,
			<7703 6748 5557 5147 5086 5077>,
			<7663 6760 5561 5153 5096 5088>,
			<7711 6830 5602 5168 5107 5096>,
			<7832 6980 5655 5173 5096 5082>,
			<7970 7136 5691 5154 5084 5068>,
			<8161 7323 5756 5163 5086 5072>,
			<8484 7602 5900 5187 5094 5081>,
			<9486 7911 6103 5226 5115 5100>,
			<9486 7911 6103 5226 5115 5100>,
			<9486 7911 6103 5226 5115 5100>;
	};
};
